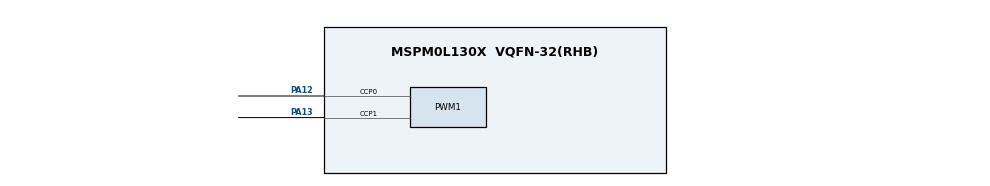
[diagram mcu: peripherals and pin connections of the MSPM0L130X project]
/**
 * @cliArgs --device "MSPM0L130X" --package "VQFN-32(RHB)" --part "Default" --product "mspm0_sdk@1.00.01.03"
 * @versions {"tool":"1.16.1+2960"}
 */

/**
 * Import the modules used in this configuration.
 */
const Board  = scripting.addModule("/ti/driverlib/Board");
const GPIO   = scripting.addModule("/ti/driverlib/GPIO", {}, false);
const GPIO1  = GPIO.addInstance();
const PWM    = scripting.addModule("/ti/driverlib/PWM", {}, false);
const PWM1   = PWM.addInstance();
const SYSCTL = scripting.addModule("/ti/driverlib/SYSCTL");

/**
 * Write custom configuration values to the imported modules.
 */

GPIO1.$name                          = "GPIO_GRP_0";
GPIO1.associatedPins[0].assignedPort = "PORTA";
GPIO1.associatedPins[0].assignedPin  = "14";
GPIO1.associatedPins[0].$name        = "LED";

PWM1.$name                      = "PWM_0";
PWM1.clockSource                = "MFCLK";
PWM1.clockDivider               = 4;
PWM1.clockPrescale              = 10;
PWM1.peripheral.$assign         = "TIMG0";
PWM1.peripheral.ccp0Pin.$assign = "PA12";
PWM1.peripheral.ccp1Pin.$assign = "PA13";
PWM1.PWM_CHANNEL_0.$name        = "ti_driverlib_pwm_PWMTimerCC0";
PWM1.PWM_CHANNEL_0.ccValue      = 500;
PWM1.PWM_CHANNEL_0.dutyCycle    = 50;
PWM1.PWM_CHANNEL_0.invert       = true;
PWM1.PWM_CHANNEL_1.$name        = "ti_driverlib_pwm_PWMTimerCC1";
PWM1.PWM_CHANNEL_1.ccValue      = 500;
PWM1.PWM_CHANNEL_1.dutyCycle    = 50;

SYSCTL.MFCLKEn = true;

/**
 * Pinmux solution for unlocked pins/peripherals. This ensures that minor changes to the automatic solver in a future
 * version of the tool will not impact the pinmux you originally saw.  These lines can be completely deleted in order to
 * re-solve from scratch.
 */
Board.peripheral.$suggestSolution            = "DEBUGSS";
Board.peripheral.swclkPin.$suggestSolution   = "PA20";
Board.peripheral.swdioPin.$suggestSolution   = "PA19";
GPIO1.associatedPins[0].pin.$suggestSolution = "PA14";
SYSCTL.peripheral.$suggestSolution           = "SYSCTL";
